AUTOSAR XML (schema 00048)
package /ComponentTypes
  swc implementation IIC_Implementation: behavior=IIC_InternalBehavior
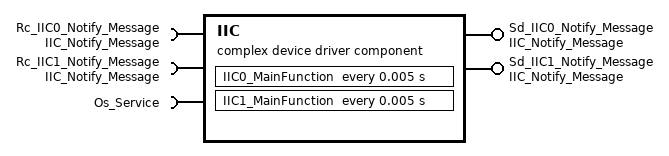
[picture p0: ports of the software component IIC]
  complex device driver sw component type IIC
    require port Rc_IIC0_Notify_Message: queued-receiver-com-spec{data-element=Message, queue-length=10}, required-interface=IIC_Notify_Message
    provide port Sd_IIC0_Notify_Message: queued-sender-com-spec=Message, provided-interface=IIC_Notify_Message
    require port Rc_IIC1_Notify_Message: queued-receiver-com-spec{data-element=Message, queue-length=10}, required-interface=IIC_Notify_Message
    provide port Sd_IIC1_Notify_Message: queued-sender-com-spec=Message, provided-interface=IIC_Notify_Message
    require port Os_Service: required-com-specs=[GetElapsedValue, GetCounterValue], required-interface=Os_Service
    behavior IIC_InternalBehavior
      exclusive area ExclusiveArea_IIC
      timing event TMT_IIC0_MainFunction: start-on-event=IIC0_MainFunction, period=0.005
      timing event TMT_IIC1_MainFunction: start-on-event=IIC1_MainFunction, period=0.005
      data received event DRT_IIC0_MainFunction_Rc_IIC0_Notify_Message_Message: start-on-event=IIC0_MainFunction, data=Rc_IIC0_Notify_Message.Message
      data received event DRT_IIC1_MainFunction_Rc_IIC1_Notify_Message_Message: start-on-event=IIC1_MainFunction, data=Rc_IIC1_Notify_Message.Message
      runnable IIC0_MainFunction: can-enter-exclusive-area=ExclusiveArea_IIC
        data-receive-point-by-arguments:
          access REC_Rc_IIC0_Notify_Message_Message: accessed-variable=Rc_IIC0_Notify_Message.Message
        data-send-points:
          access SEND_Sd_IIC_Notify_Message_Message: accessed-variable=Sd_IIC0_Notify_Message.Message
        sync call SC_Os_Service_GetCounterValue: operation=Os_Service.GetCounterValue
        sync call SC_Os_Service_GetElapsedValue: operation=Os_Service.GetElapsedValue
      runnable IIC1_MainFunction: can-enter-exclusive-area=ExclusiveArea_IIC
        data-receive-point-by-arguments:
          access REC_Rc_IIC1_Notify_Message_Message: accessed-variable=Rc_IIC1_Notify_Message.Message
        data-send-points:
          access SEND_Sd_IIC1_Notify_Message_Message: accessed-variable=Sd_IIC1_Notify_Message.Message
        sync call SC_Os_Service_GetCounterValue: operation=Os_Service.GetCounterValue
        sync call SC_Os_Service_GetElapsedValue: operation=Os_Service.GetElapsedValue
